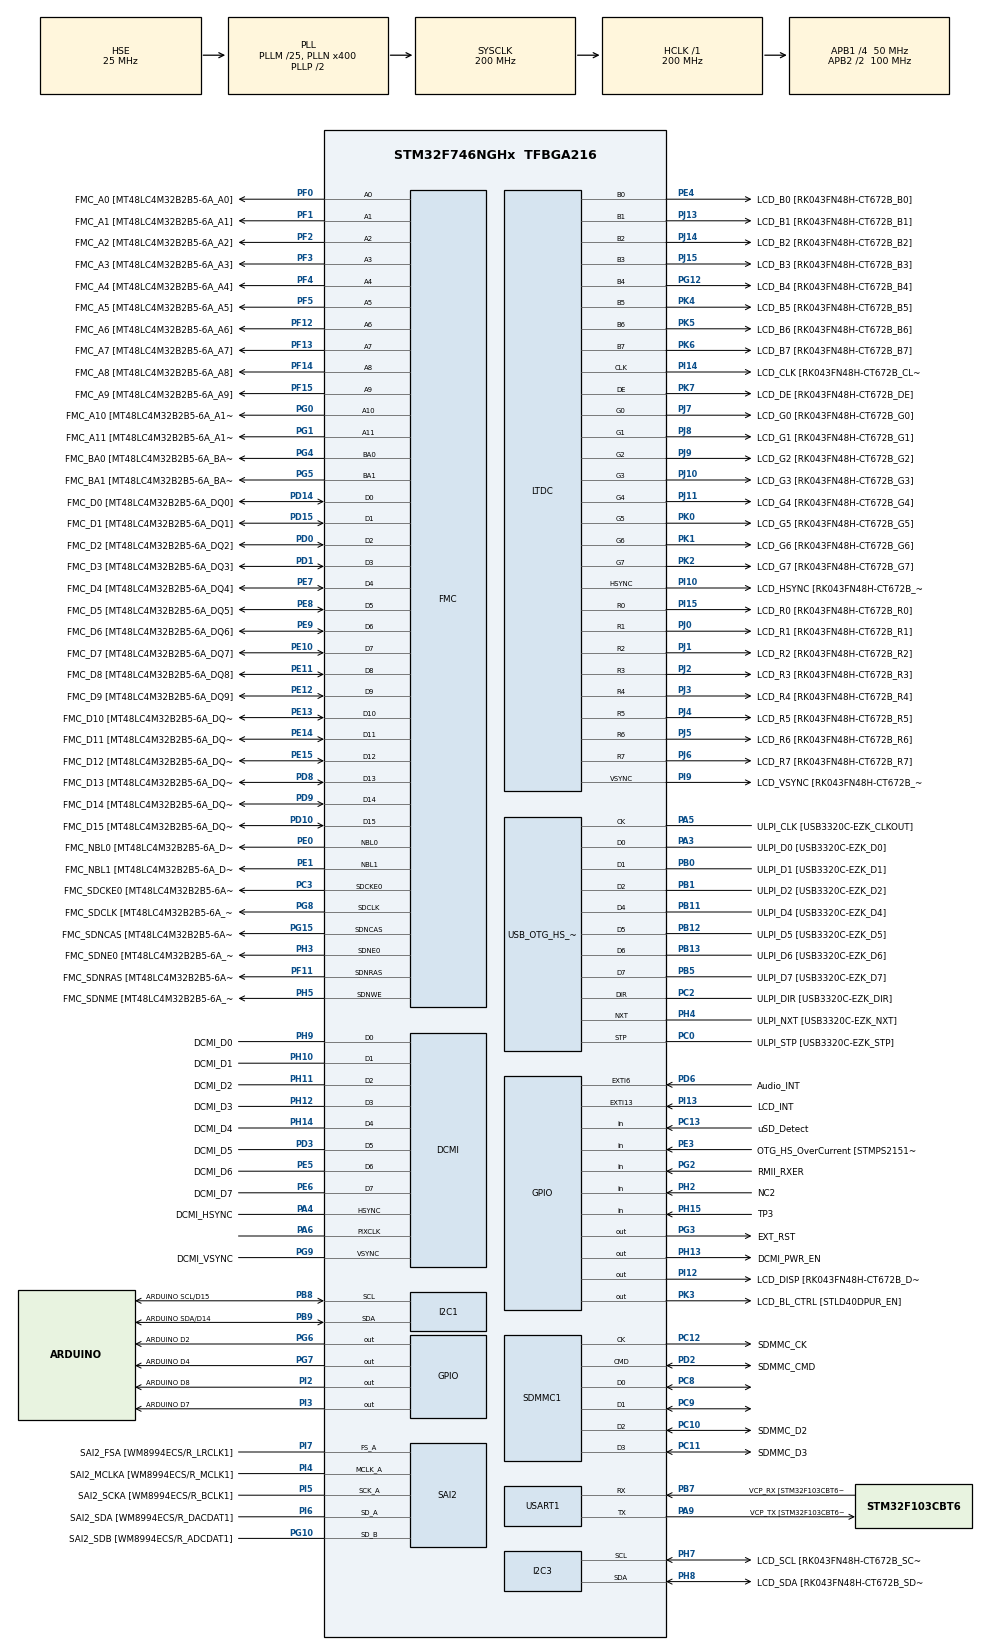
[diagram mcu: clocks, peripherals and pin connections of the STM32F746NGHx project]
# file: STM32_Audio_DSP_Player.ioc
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Dma.Request0=SDMMC1_RX
Dma.Request1=SDMMC1_TX
Dma.SDMMC1_RX.0.Direction=DMA_PERIPH_TO_MEMORY
Dma.SDMMC1_RX.0.FIFOMode=DMA_FIFOMODE_ENABLE
Dma.SDMMC1_RX.0.FIFOThreshold=DMA_FIFO_THRESHOLD_FULL
Dma.SDMMC1_RX.0.Instance=DMA2_Stream3
Dma.SDMMC1_RX.0.MemBurst=DMA_MBURST_INC4
Dma.SDMMC1_RX.0.MemDataAlignment=DMA_MDATAALIGN_WORD
Dma.SDMMC1_RX.0.MemInc=DMA_MINC_ENABLE
Dma.SDMMC1_RX.0.Mode=DMA_PFCTRL
Dma.SDMMC1_RX.0.PeriphBurst=DMA_PBURST_INC4
Dma.SDMMC1_RX.0.PeriphDataAlignment=DMA_PDATAALIGN_WORD
Dma.SDMMC1_RX.0.PeriphInc=DMA_PINC_DISABLE
Dma.SDMMC1_RX.0.Priority=DMA_PRIORITY_LOW
Dma.SDMMC1_TX.1.Direction=DMA_MEMORY_TO_PERIPH
Dma.SDMMC1_TX.1.FIFOMode=DMA_FIFOMODE_ENABLE
Dma.SDMMC1_TX.1.FIFOThreshold=DMA_FIFO_THRESHOLD_FULL
Dma.SDMMC1_TX.1.Instance=DMA2_Stream6
Dma.SDMMC1_TX.1.MemBurst=DMA_MBURST_INC4
Dma.SDMMC1_TX.1.MemDataAlignment=DMA_MDATAALIGN_WORD
Dma.SDMMC1_TX.1.MemInc=DMA_MINC_ENABLE
Dma.SDMMC1_TX.1.Mode=DMA_PFCTRL
Dma.SDMMC1_TX.1.PeriphBurst=DMA_PBURST_INC4
Dma.SDMMC1_TX.1.PeriphDataAlignment=DMA_PDATAALIGN_WORD
Dma.SDMMC1_TX.1.PeriphInc=DMA_PINC_DISABLE
Dma.SDMMC1_TX.1.Priority=DMA_PRIORITY_LOW
FATFS.BSP.number=1
FATFS0.BSP.STBoard=false
FATFS0.BSP.api=Unknown
FATFS0.BSP.instance=PC13
FATFS0.BSP.ip=GPIO
FATFS0.BSP.mode=Input
FATFS0.BSP.name=Detect_SDIO
FATFS0.BSP.solution=PC13
FMC.CASLatency1=FMC_SDRAM_CAS_LATENCY_3
FMC.ExitSelfRefreshDelay1=7
FMC.LoadToActiveDelay1=2
FMC.RCDDelay1=2
FMC.RPDelay1=2
FMC.RPDelay2=2
FMC.ReadBurst1=FMC_SDRAM_RBURST_ENABLE
FMC.ReadBurst2=FMC_SDRAM_RBURST_ENABLE
FMC.RowCycleDelay1=7
FMC.RowCycleDelay2=7
FMC.SDClockPeriod1=FMC_SDRAM_CLOCK_PERIOD_2
FMC.SDClockPeriod2=FMC_SDRAM_CLOCK_PERIOD_2
FMC.SelfRefreshTime1=4
FMC.WriteRecoveryTime1=3
FREERTOS.Tasks01=defaultTask,0,4096,StartDefaultTask,Default,NULL,Dynamic,NULL,NULL;TouchGFXTask,0,4096,TouchGFX_Task,As external,NULL,Dynamic,NULL,NULL
FREERTOS.configCHECK_FOR_STACK_OVERFLOW=2
FREERTOS.configTOTAL_HEAP_SIZE=70000
FREERTOS.configUSE_APPLICATION_TASK_TAG=1
FREERTOS.configUSE_COUNTING_SEMAPHORES=1
FREERTOS.configUSE_IDLE_HOOK=1
FREERTOS.configUSE_MALLOC_FAILED_HOOK=1
FREERTOS.configUSE_RECURSIVE_MUTEXES=1
I2C1.Timing=0x00C0EAFF
I2C3.Timing=0x00C0EAFF
LTDC.ActiveH=272
LTDC.ActiveW=480
LTDC.Alpha_L0=255
LTDC.BlendingFactor1_L0=LTDC_BLENDING_FACTOR1_PAxCA
LTDC.BlendingFactor2_L0=LTDC_BLENDING_FACTOR2_PAxCA
LTDC.FBStartAdress_L0=0xC0000000
LTDC.HBP=13
LTDC.HFP=32
LTDC.HSync=41
LTDC.ImageHeight_L0=272
LTDC.ImageWidth_L0=480
LTDC.Layers=0
LTDC.PixelFormat_L0=LTDC_PIXEL_FORMAT_RGB565
LTDC.VSync=10
LTDC.WindowX1_L0=480
LTDC.WindowY1_L0=272
Mcu.Family=STM32F7
Mcu.Name=STM32F746NGHx
Mcu.Package=TFBGA216
NVIC.DMA2D_IRQn=true\:5\:0\:false\:false\:true\:true\:true\:true\:true
NVIC.DMA2_Stream3_IRQn=true\:5\:0\:false\:false\:true\:true\:false\:true\:true
NVIC.DMA2_Stream6_IRQn=true\:5\:0\:false\:false\:true\:true\:false\:true\:true
NVIC.LTDC_IRQn=true\:5\:0\:false\:false\:true\:true\:true\:true\:true
NVIC.PriorityGroup=NVIC_PRIORITYGROUP_4
NVIC.SDMMC1_IRQn=true\:5\:0\:false\:false\:true\:true\:true\:true\:true
NVIC.TIM6_DAC_IRQn=true\:0\:0\:false\:false\:true\:false\:false\:true\:true
NVIC.TimeBase=TIM6_DAC_IRQn
NVIC.TimeBaseIP=TIM6
PA0/WKUP.GPIO_Label=ARDUINO A0
PA0/WKUP.GPIO_Mode=GPIO_MODE_ANALOG
PA0/WKUP.GPIO_PuPd=GPIO_NOPULL
PA0/WKUP.Signal=ADCx_IN0
PA1.GPIO_Label=RMII_REF_CLK [LAN8742A-CZ-TR_REFCLK0]
PA1.Signal=ETH_REF_CLK
PA13.GPIO_Label=SWDIO
PA13.Mode=Serial_Wire
PA13.Signal=SYS_JTMS-SWDIO
PA14.GPIO_Label=SWCLK
PA14.Mode=Serial_Wire
PA14.Signal=SYS_JTCK-SWCLK
PA15.GPIO_Label=ARDUINO PWM/D9
PA15.GPIO_PuPd=GPIO_NOPULL
PA15.GPIO_Speed=GPIO_SPEED_FREQ_LOW
PA15.Signal=S_TIM2_CH1_ETR
PA2.GPIO_Label=RMII_MDIO [LAN8742A-CZ-TR_MDIO]
PA2.Signal=ETH_MDIO
PA3.GPIO_Label=ULPI_D0 [USB3320C-EZK_D0]
PA3.Mode=Host_HS
PA3.Signal=USB_OTG_HS_ULPI_D0
PA4.GPIO_Label=DCMI_HSYNC
PA4.Mode=Slave_8_bits_External_Synchro
PA4.Signal=DCMI_HSYNC
PA5.GPIO_Label=ULPI_CLK [USB3320C-EZK_CLKOUT]
PA5.Mode=Host_HS
PA5.Signal=USB_OTG_HS_ULPI_CK
PA6.Mode=Slave_8_bits_External_Synchro
PA6.Signal=DCMI_PIXCLK
PA7.GPIO_Label=RMII_CRS_DV [LAN8742A-CZ-TR_CRS_DV]
PA7.Signal=ETH_CRS_DV
PA8.GPIO_Label=ARDUINO PWM/D10
PA8.GPIO_PuPd=GPIO_NOPULL
PA8.GPIO_Speed=GPIO_SPEED_FREQ_LOW
PA8.Signal=S_TIM1_CH1
PA9.GPIO_Label=VCP_TX [STM32F103CBT6_PA3]
PA9.GPIO_Mode=GPIO_MODE_AF_PP
PA9.GPIO_PuPd=GPIO_NOPULL
PA9.GPIO_Speed=GPIO_SPEED_FREQ_LOW
PA9.Mode=Asynchronous
PA9.Signal=USART1_TX
PB0.GPIO_Label=ULPI_D1 [USB3320C-EZK_D1]
PB0.Mode=Host_HS
PB0.Signal=USB_OTG_HS_ULPI_D1
PB1.GPIO_Label=ULPI_D2 [USB3320C-EZK_D2]
PB1.Mode=Host_HS
PB1.Signal=USB_OTG_HS_ULPI_D2
PB10.GPIO_Label=ULPI_D3 [USB3320C-EZK_D3]
PB10.Signal=USB_OTG_HS_ULPI_D3
PB11.GPIO_Label=ULPI_D4 [USB3320C-EZK_D4]
PB11.Mode=Host_HS
PB11.Signal=USB_OTG_HS_ULPI_D4
PB12.GPIO_Label=ULPI_D5 [USB3320C-EZK_D5]
PB12.Mode=Host_HS
PB12.Signal=USB_OTG_HS_ULPI_D5
PB13.GPIO_Label=ULPI_D6 [USB3320C-EZK_D6]
PB13.Mode=Host_HS
PB13.Signal=USB_OTG_HS_ULPI_D6
PB14.GPIO_Label=ARDUINO MISO/D12
PB14.GPIO_Mode=GPIO_MODE_AF_PP
PB14.GPIO_PuPd=GPIO_NOPULL
PB14.GPIO_Speed=GPIO_SPEED_FREQ_LOW
PB14.Signal=SPI2_MISO
PB15.GPIO_Label=ARDUINO MOSI/PWM/D11
PB15.GPIO_Mode=GPIO_MODE_AF_PP
PB15.GPIO_PuPd=GPIO_NOPULL
PB15.GPIO_Speed=GPIO_SPEED_FREQ_LOW
PB15.Signal=SPI2_MOSI
PB3.GPIO_Label=SWO
PB3.Signal=SYS_JTDO-SWO
PB5.GPIO_Label=ULPI_D7 [USB3320C-EZK_D7]
PB5.Mode=Host_HS
PB5.Signal=USB_OTG_HS_ULPI_D7
PB7.GPIO_Label=VCP_RX [STM32F103CBT6_PA2]
PB7.GPIO_Mode=GPIO_MODE_AF_PP
PB7.GPIO_PuPd=GPIO_NOPULL
PB7.GPIO_Speed=GPIO_SPEED_FREQ_LOW
PB7.Mode=Asynchronous
PB7.Signal=USART1_RX
PB8.GPIO_Label=ARDUINO SCL/D15
PB8.GPIO_Mode=GPIO_MODE_AF_OD
PB8.GPIO_Pu=GPIO_PULLUP
PB8.GPIO_PuPd=GPIO_NOPULL
PB8.GPIO_Speed=GPIO_SPEED_FREQ_LOW
PB8.Mode=I2C
PB8.Signal=I2C1_SCL
PB9.GPIO_Label=ARDUINO SDA/D14
PB9.GPIO_Mode=GPIO_MODE_AF_OD
PB9.GPIO_Pu=GPIO_PULLUP
PB9.GPIO_PuPd=GPIO_NOPULL
PB9.GPIO_Speed=GPIO_SPEED_FREQ_LOW
PB9.Mode=I2C
PB9.Signal=I2C1_SDA
PC0.GPIO_Label=ULPI_STP [USB3320C-EZK_STP]
PC0.Mode=Host_HS
PC0.Signal=USB_OTG_HS_ULPI_STP
PC1.GPIO_Label=RMII_MDC [LAN8742A-CZ-TR_MDC]
PC1.Signal=ETH_MDC
PC10.GPIO_Label=SDMMC_D2
PC10.Mode=SD_4_bits_Wide_bus
PC10.Signal=SDMMC1_D2
PC11.GPIO_Label=SDMMC_D3
PC11.Mode=SD_4_bits_Wide_bus
PC11.Signal=SDMMC1_D3
PC12.GPIO_Label=SDMMC_CK
PC12.Mode=SD_4_bits_Wide_bus
PC12.Signal=SDMMC1_CK
PC13.GPIO_Label=uSD_Detect
PC13.GPIO_PuPd=GPIO_PULLUP
PC13.Signal=GPIO_Input
PC14/OSC32_IN.GPIO_Label=RCC_OSC32_IN
PC14/OSC32_IN.Mode=LSE-External-Oscillator
PC14/OSC32_IN.Signal=RCC_OSC32_IN
PC15/OSC32_OUT.GPIO_Label=RCC_OSC32_OUT
PC15/OSC32_OUT.Mode=LSE-External-Oscillator
PC15/OSC32_OUT.Signal=RCC_OSC32_OUT
PC2.GPIO_Label=ULPI_DIR [USB3320C-EZK_DIR]
PC2.Mode=Host_HS
PC2.Signal=USB_OTG_HS_ULPI_DIR
PC3.GPIO_Label=FMC_SDCKE0 [MT48LC4M32B2B5-6A_CKE]
PC3.Mode=SdramChipSelect1_1
PC3.Signal=FMC_SDCKE0
PC4.GPIO_Label=RMII_RXD0 [LAN8742A-CZ-TR_RXD0]
PC4.Signal=ETH_RXD0
PC5.GPIO_Label=RMII_RXD1 [LAN8742A-CZ-TR_RXD1]
PC5.Signal=ETH_RXD1
PC8.Mode=SD_4_bits_Wide_bus
PC8.Signal=SDMMC1_D0
PC9.Mode=SD_4_bits_Wide_bus
PC9.Signal=SDMMC1_D1
PD0.GPIO_Label=FMC_D2 [MT48LC4M32B2B5-6A_DQ2]
PD0.Signal=FMC_D2_DA2
PD1.GPIO_Label=FMC_D3 [MT48LC4M32B2B5-6A_DQ3]
PD1.Signal=FMC_D3_DA3
PD10.GPIO_Label=FMC_D15 [MT48LC4M32B2B5-6A_DQ15]
PD10.Signal=FMC_D15_DA15
PD14.GPIO_Label=FMC_D0 [MT48LC4M32B2B5-6A_DQ0]
PD14.Signal=FMC_D0_DA0
PD15.GPIO_Label=FMC_D1 [MT48LC4M32B2B5-6A_DQ1]
PD15.Signal=FMC_D1_DA1
PD2.GPIO_Label=SDMMC_CMD
PD2.Mode=SD_4_bits_Wide_bus
PD2.Signal=SDMMC1_CMD
PD3.GPIO_Label=DCMI_D5
PD3.Mode=Slave_8_bits_External_Synchro
PD3.Signal=DCMI_D5
PD6.GPIO_Label=Audio_INT
PD6.GPIO_ModeDefaultEXTI=GPIO_MODE_EVT_RISING
PD6.Signal=GPXTI6
PD7.GPIO_Label=SPDIF_RX0 [74LVC1G04SE_4]
PD7.Signal=SPDIFRX_IN0
PD8.GPIO_Label=FMC_D13 [MT48LC4M32B2B5-6A_DQ13]
PD8.Signal=FMC_D13_DA13
PD9.GPIO_Label=FMC_D14 [MT48LC4M32B2B5-6A_DQ14]
PD9.Signal=FMC_D14_DA14
PE0.GPIO_Label=FMC_NBL0 [MT48LC4M32B2B5-6A_DQM0]
PE0.Signal=FMC_NBL0
PE1.GPIO_Label=FMC_NBL1 [MT48LC4M32B2B5-6A_DQM1]
PE1.Signal=FMC_NBL1
PE10.GPIO_Label=FMC_D7 [MT48LC4M32B2B5-6A_DQ7]
PE10.Signal=FMC_D7_DA7
PE11.GPIO_Label=FMC_D8 [MT48LC4M32B2B5-6A_DQ8]
PE11.Signal=FMC_D8_DA8
PE12.GPIO_Label=FMC_D9 [MT48LC4M32B2B5-6A_DQ9]
PE12.Signal=FMC_D9_DA9
PE13.GPIO_Label=FMC_D10 [MT48LC4M32B2B5-6A_DQ10]
PE13.Signal=FMC_D10_DA10
PE14.GPIO_Label=FMC_D11 [MT48LC4M32B2B5-6A_DQ11]
PE14.Signal=FMC_D11_DA11
PE15.GPIO_Label=FMC_D12 [MT48LC4M32B2B5-6A_DQ12]
PE15.Signal=FMC_D12_DA12
PE3.GPIO_Label=OTG_HS_OverCurrent [STMPS2151STR_FAULT]
PE3.Signal=GPIO_Input
PE4.GPIO_Label=LCD_B0 [RK043FN48H-CT672B_B0]
PE4.Mode=RGB888
PE4.Signal=LTDC_B0
PE5.GPIO_Label=DCMI_D6
PE5.Mode=Slave_8_bits_External_Synchro
PE5.Signal=DCMI_D6
PE6.GPIO_Label=DCMI_D7
PE6.Mode=Slave_8_bits_External_Synchro
PE6.Signal=DCMI_D7
PE7.GPIO_Label=FMC_D4 [MT48LC4M32B2B5-6A_DQ4]
PE7.Signal=FMC_D4_DA4
PE8.GPIO_Label=FMC_D5 [MT48LC4M32B2B5-6A_DQ5]
PE8.Signal=FMC_D5_DA5
PE9.GPIO_Label=FMC_D6 [MT48LC4M32B2B5-6A_DQ6]
PE9.Signal=FMC_D6_DA6
PF0.GPIO_Label=FMC_A0 [MT48LC4M32B2B5-6A_A0]
PF0.Signal=FMC_A0
PF1.GPIO_Label=FMC_A1 [MT48LC4M32B2B5-6A_A1]
PF1.Signal=FMC_A1
PF10.GPIO_Label=ARDUINO A1
PF10.GPIO_Mode=GPIO_MODE_ANALOG
PF10.GPIO_PuPd=GPIO_NOPULL
PF10.Signal=ADC3_IN8
PF11.GPIO_Label=FMC_SDNRAS [MT48LC4M32B2B5-6A_RAS]
PF11.Signal=FMC_SDNRAS
PF12.GPIO_Label=FMC_A6 [MT48LC4M32B2B5-6A_A6]
PF12.Signal=FMC_A6
PF13.GPIO_Label=FMC_A7 [MT48LC4M32B2B5-6A_A7]
PF13.Signal=FMC_A7
PF14.GPIO_Label=FMC_A8 [MT48LC4M32B2B5-6A_A8]
PF14.Signal=FMC_A8
PF15.GPIO_Label=FMC_A9 [MT48LC4M32B2B5-6A_A9]
PF15.Signal=FMC_A9
PF2.GPIO_Label=FMC_A2 [MT48LC4M32B2B5-6A_A2]
PF2.Signal=FMC_A2
PF3.GPIO_Label=FMC_A3 [MT48LC4M32B2B5-6A_A3]
PF3.Signal=FMC_A3
PF4.GPIO_Label=FMC_A4 [MT48LC4M32B2B5-6A_A4]
PF4.Signal=FMC_A4
PF5.GPIO_Label=FMC_A5 [MT48LC4M32B2B5-6A_A5]
PF5.Signal=FMC_A5
PF6.GPIO_Label=ARDUINO A5
PF6.GPIO_Mode=GPIO_MODE_ANALOG
PF6.GPIO_PuPd=GPIO_NOPULL
PF6.Signal=ADC3_IN4
PF7.GPIO_Label=ARDUINO A4
PF7.GPIO_Mode=GPIO_MODE_ANALOG
PF7.GPIO_PuPd=GPIO_NOPULL
PF7.Signal=ADC3_IN5
PF8.GPIO_Label=ARDUINO A3
PF8.GPIO_Mode=GPIO_MODE_ANALOG
PF8.GPIO_PuPd=GPIO_NOPULL
PF8.Signal=ADC3_IN6
PF9.GPIO_Label=ARDUINO A2
PF9.GPIO_Mode=GPIO_MODE_ANALOG
PF9.GPIO_PuPd=GPIO_NOPULL
PF9.Signal=ADC3_IN7
PG0.GPIO_Label=FMC_A10 [MT48LC4M32B2B5-6A_A10]
PG0.Signal=FMC_A10
PG1.GPIO_Label=FMC_A11 [MT48LC4M32B2B5-6A_A11]
PG1.Signal=FMC_A11
PG10.GPIO_Label=SAI2_SDB [WM8994ECS/R_ADCDAT1]
PG10.Mode=SAI_B_SyncSlave
PG10.Signal=SAI2_SD_B
PG11.GPIO_Label=RMII_TX_EN [LAN8742A-CZ-TR_TXEN]
PG11.Signal=ETH_TX_EN
PG12.GPIO_Label=LCD_B4 [RK043FN48H-CT672B_B4]
PG12.Mode=RGB888
PG12.Signal=LTDC_B4
PG13.GPIO_Label=RMII_TXD0 [LAN8742A-CZ-TR_TXD0]
PG13.Signal=ETH_TXD0
PG14.GPIO_Label=RMII_TXD1 [LAN8742A-CZ-TR_TXD1]
PG14.Signal=ETH_TXD1
PG15.GPIO_Label=FMC_SDNCAS [MT48LC4M32B2B5-6A_CAS]
PG15.Signal=FMC_SDNCAS
PG2.GPIO_Label=RMII_RXER
PG2.Signal=GPIO_Input
PG3.GPIO_Label=EXT_RST
PG3.Signal=GPIO_Output
PG4.GPIO_Label=FMC_BA0 [MT48LC4M32B2B5-6A_BA0]
PG4.Signal=FMC_A14_BA0
PG5.GPIO_Label=FMC_BA1 [MT48LC4M32B2B5-6A_BA1]
PG5.Signal=FMC_A15_BA1
PG6.GPIO_Label=ARDUINO D2
PG6.Signal=GPIO_Output
PG7.GPIO_Label=ARDUINO D4
PG7.Signal=GPIO_Output
PG8.GPIO_Label=FMC_SDCLK [MT48LC4M32B2B5-6A_CLK]
PG8.Signal=FMC_SDCLK
PG9.GPIO_Label=DCMI_VSYNC
PG9.Mode=Slave_8_bits_External_Synchro
PG9.Signal=DCMI_VSYNC
PH0/OSC_IN.GPIO_Label=OSC_25M [NZ2520SB-25.00M_OUT]
PH0/OSC_IN.Mode=HSE-External-Oscillator
PH0/OSC_IN.Signal=RCC_OSC_IN
PH1/OSC_OUT.Mode=HSE-External-Oscillator
PH1/OSC_OUT.Signal=RCC_OSC_OUT
PH10.GPIO_Label=DCMI_D1
PH10.Mode=Slave_8_bits_External_Synchro
PH10.Signal=DCMI_D1
PH11.GPIO_Label=DCMI_D2
PH11.Mode=Slave_8_bits_External_Synchro
PH11.Signal=DCMI_D2
PH12.GPIO_Label=DCMI_D3
PH12.Mode=Slave_8_bits_External_Synchro
PH12.Signal=DCMI_D3
PH13.GPIO_Label=DCMI_PWR_EN
PH13.Signal=GPIO_Output
PH14.GPIO_Label=DCMI_D4
PH14.Mode=Slave_8_bits_External_Synchro
PH14.Signal=DCMI_D4
PH15.GPIO_Label=TP3
PH15.Signal=GPIO_Input
PH2.GPIO_Label=NC2
PH2.Signal=GPIO_Input
PH3.GPIO_Label=FMC_SDNE0 [MT48LC4M32B2B5-6A_CS]
PH3.Mode=SdramChipSelect1_1
PH3.Signal=FMC_SDNE0
PH4.GPIO_Label=ULPI_NXT [USB3320C-EZK_NXT]
PH4.Mode=Host_HS
PH4.Signal=USB_OTG_HS_ULPI_NXT
PH5.GPIO_Label=FMC_SDNME [MT48LC4M32B2B5-6A_WE]
PH5.Signal=FMC_SDNWE
PH7.GPIO_Label=LCD_SCL [RK043FN48H-CT672B_SCL]
PH7.GPIO_Pu=GPIO_PULLUP
PH7.Mode=I2C
PH7.Signal=I2C3_SCL
PH8.GPIO_Label=LCD_SDA [RK043FN48H-CT672B_SDA]
PH8.GPIO_Pu=GPIO_PULLUP
PH8.Mode=I2C
PH8.Signal=I2C3_SDA
PH9.GPIO_Label=DCMI_D0
PH9.Mode=Slave_8_bits_External_Synchro
PH9.Signal=DCMI_D0
PI1.GPIO_Label=ARDUINO SCK/D13
PI1.GPIO_Mode=GPIO_MODE_AF_PP
PI1.GPIO_PuPd=GPIO_NOPULL
PI1.GPIO_Speed=GPIO_SPEED_FREQ_LOW
PI1.Signal=SPI2_SCK
PI10.GPIO_Label=LCD_HSYNC [RK043FN48H-CT672B_HSYNC]
PI10.Mode=RGB888
PI10.Signal=LTDC_HSYNC
PI12.GPIO_Label=LCD_DISP [RK043FN48H-CT672B_DISP] 
PI12.PinState=GPIO_PIN_SET
PI12.Signal=GPIO_Output
PI13.GPIO_Label=LCD_INT
PI13.GPIO_ModeDefaultEXTI=GPIO_MODE_EVT_RISING
PI13.Signal=GPXTI13
PI14.GPIO_Label=LCD_CLK [RK043FN48H-CT672B_CLK]
PI14.Mode=RGB888
PI14.Signal=LTDC_CLK
PI15.GPIO_Label=LCD_R0 [RK043FN48H-CT672B_R0]
PI15.Mode=RGB888
PI15.Signal=LTDC_R0
PI2.GPIO_Label=ARDUINO D8
PI2.Signal=GPIO_Output
PI3.GPIO_Label=ARDUINO D7
PI3.Signal=GPIO_Output
PI4.GPIO_Label=SAI2_MCLKA [WM8994ECS/R_MCLK1]
PI4.Mode=SAI_A_MasterWithClock
PI4.Signal=SAI2_MCLK_A
PI5.GPIO_Label=SAI2_SCKA [WM8994ECS/R_BCLK1]
PI5.Mode=SAI_A_MasterWithClock
PI5.Signal=SAI2_SCK_A
PI6.GPIO_Label=SAI2_SDA [WM8994ECS/R_DACDAT1]
PI6.Mode=SAI_A_MasterWithClock
PI6.Signal=SAI2_SD_A
PI7.GPIO_Label=SAI2_FSA [WM8994ECS/R_LRCLK1]
PI7.Mode=SAI_A_MasterWithClock
PI7.Signal=SAI2_FS_A
PI8.GPIO_Label=NC1 [TP2]
PI8.Signal=RTC_TS
PI9.GPIO_Label=LCD_VSYNC [RK043FN48H-CT672B_VSYNC]
PI9.Mode=RGB888
PI9.Signal=LTDC_VSYNC
PJ0.GPIO_Label=LCD_R1 [RK043FN48H-CT672B_R1]
PJ0.Mode=RGB888
PJ0.Signal=LTDC_R1
PJ1.GPIO_Label=LCD_R2 [RK043FN48H-CT672B_R2]
PJ1.Mode=RGB888
PJ1.Signal=LTDC_R2
PJ10.GPIO_Label=LCD_G3 [RK043FN48H-CT672B_G3]
PJ10.Mode=RGB888
PJ10.Signal=LTDC_G3
PJ11.GPIO_Label=LCD_G4 [RK043FN48H-CT672B_G4]
PJ11.Mode=RGB888
PJ11.Signal=LTDC_G4
PJ13.GPIO_Label=LCD_B1 [RK043FN48H-CT672B_B1]
PJ13.Mode=RGB888
PJ13.Signal=LTDC_B1
PJ14.GPIO_Label=LCD_B2 [RK043FN48H-CT672B_B2]
PJ14.Mode=RGB888
PJ14.Signal=LTDC_B2
PJ15.GPIO_Label=LCD_B3 [RK043FN48H-CT672B_B3]
PJ15.Mode=RGB888
PJ15.Signal=LTDC_B3
PJ2.GPIO_Label=LCD_R3 [RK043FN48H-CT672B_R3]
PJ2.Mode=RGB888
PJ2.Signal=LTDC_R3
PJ3.GPIO_Label=LCD_R4 [RK043FN48H-CT672B_R4]
PJ3.Mode=RGB888
PJ3.Signal=LTDC_R4
PJ4.GPIO_Label=LCD_R5 [RK043FN48H-CT672B_R5]
PJ4.Mode=RGB888
PJ4.Signal=LTDC_R5
PJ5.GPIO_Label=LCD_R6 [RK043FN48H-CT672B_R6]
PJ5.Mode=RGB888
PJ5.Signal=LTDC_R6
PJ6.GPIO_Label=LCD_R7 [RK043FN48H-CT672B_R7]
PJ6.Mode=RGB888
PJ6.Signal=LTDC_R7
PJ7.GPIO_Label=LCD_G0 [RK043FN48H-CT672B_G0]
PJ7.Mode=RGB888
PJ7.Signal=LTDC_G0
PJ8.GPIO_Label=LCD_G1 [RK043FN48H-CT672B_G1]
PJ8.Mode=RGB888
PJ8.Signal=LTDC_G1
PJ9.GPIO_Label=LCD_G2 [RK043FN48H-CT672B_G2]
PJ9.Mode=RGB888
PJ9.Signal=LTDC_G2
PK0.GPIO_Label=LCD_G5 [RK043FN48H-CT672B_G5]
PK0.Mode=RGB888
PK0.Signal=LTDC_G5
PK1.GPIO_Label=LCD_G6 [RK043FN48H-CT672B_G6]
PK1.Mode=RGB888
PK1.Signal=LTDC_G6
PK2.GPIO_Label=LCD_G7 [RK043FN48H-CT672B_G7]
PK2.Mode=RGB888
PK2.Signal=LTDC_G7
PK3.GPIO_Label=LCD_BL_CTRL [STLD40DPUR_EN]
PK3.GPIO_Speed=GPIO_SPEED_FREQ_LOW
PK3.PinState=GPIO_PIN_SET
PK3.Signal=GPIO_Output
PK4.GPIO_Label=LCD_B5 [RK043FN48H-CT672B_B5]
PK4.Mode=RGB888
PK4.Signal=LTDC_B5
PK5.GPIO_Label=LCD_B6 [RK043FN48H-CT672B_B6]
PK5.Mode=RGB888
PK5.Signal=LTDC_B6
PK6.GPIO_Label=LCD_B7 [RK043FN48H-CT672B_B7]
PK6.Mode=RGB888
PK6.Signal=LTDC_B7
PK7.GPIO_Label=LCD_DE [RK043FN48H-CT672B_DE]
PK7.Mode=RGB888
PK7.Signal=LTDC_DE
ProjectManager.HeapSize=0x200
ProjectManager.StackSize=0x400
ProjectManager.TargetToolchain=STM32CubeIDE
RCC.AHBFreq_Value=200000000
RCC.APB1CLKDivider=RCC_HCLK_DIV4
RCC.APB1Freq_Value=50000000
RCC.APB1TimFreq_Value=100000000
RCC.APB2CLKDivider=RCC_HCLK_DIV2
RCC.APB2Freq_Value=100000000
RCC.APB2TimFreq_Value=200000000
RCC.CortexFreq_Value=200000000
RCC.HCLKFreq_Value=200000000
RCC.HSE_VALUE=25000000
RCC.HSI_VALUE=16000000
RCC.PLL48CLockSelection=RCC_CLK48SOURCE_PLLSAIP
RCC.PLLI2SN=100
RCC.PLLM=25
RCC.PLLN=400
RCC.PLLQ=9
RCC.PLLSAIN=384
RCC.PLLSAIP=RCC_PLLSAIP_DIV8
RCC.PLLSAIR=5
RCC.PLLSAIRDiv=RCC_PLLSAIDIVR_8
RCC.SDMMCClockSelection=RCC_SDMMC1CLKSOURCE_CLK48
RCC.SYSCLKFreq_VALUE=200000000
RCC.SYSCLKSource=RCC_SYSCLKSOURCE_PLLCLK
RCC.USBFreq_Value=48000000
RCC.VCOOutputFreq_Value=400000000
SAI2.ErrorAudioFreq-SAI_A_MasterWithClock=-2.34 %
SAI2.Instance-SAI_A_MasterWithClock=SAI$Index_Block_A
SAI2.Instance-SAI_B_SyncSlave=SAI$Index_Block_B
SAI2.MClockEnable-SAI_A_MasterWithClock=SAI_MASTERCLOCK_ENABLE
SAI2.RealAudioFreq-SAI_A_MasterWithClock=187.5 KHz
SAI2.Synchro-SAI_B_SyncSlave=SAI_SYNCHRONOUS
SAI2.VirtualMode-SAI_A_MasterWithClock=VM_MASTER
SAI2.VirtualMode-SAI_B_SyncSlave=VM_SLAVE
SDMMC1.WideMode=SDMMC_BUS_WIDE_4B
SH.ADCx_IN0.0=ADC3_IN0
SH.FMC_A0.0=FMC_A0,12b-sda1
SH.FMC_A1.0=FMC_A1,12b-sda1
SH.FMC_A10.0=FMC_A10,12b-sda1
SH.FMC_A11.0=FMC_A11,12b-sda1
SH.FMC_A14_BA0.0=FMC_BA0,FourSdramBanks1
SH.FMC_A15_BA1.0=FMC_BA1,FourSdramBanks1
SH.FMC_A2.0=FMC_A2,12b-sda1
SH.FMC_A3.0=FMC_A3,12b-sda1
SH.FMC_A4.0=FMC_A4,12b-sda1
SH.FMC_A5.0=FMC_A5,12b-sda1
SH.FMC_A6.0=FMC_A6,12b-sda1
SH.FMC_A7.0=FMC_A7,12b-sda1
SH.FMC_A8.0=FMC_A8,12b-sda1
SH.FMC_A9.0=FMC_A9,12b-sda1
SH.FMC_D0_DA0.0=FMC_D0,sd-16b-d1
SH.FMC_D10_DA10.0=FMC_D10,sd-16b-d1
SH.FMC_D11_DA11.0=FMC_D11,sd-16b-d1
SH.FMC_D12_DA12.0=FMC_D12,sd-16b-d1
SH.FMC_D13_DA13.0=FMC_D13,sd-16b-d1
SH.FMC_D14_DA14.0=FMC_D14,sd-16b-d1
SH.FMC_D15_DA15.0=FMC_D15,sd-16b-d1
SH.FMC_D1_DA1.0=FMC_D1,sd-16b-d1
SH.FMC_D2_DA2.0=FMC_D2,sd-16b-d1
SH.FMC_D3_DA3.0=FMC_D3,sd-16b-d1
SH.FMC_D4_DA4.0=FMC_D4,sd-16b-d1
SH.FMC_D5_DA5.0=FMC_D5,sd-16b-d1
SH.FMC_D6_DA6.0=FMC_D6,sd-16b-d1
SH.FMC_D7_DA7.0=FMC_D7,sd-16b-d1
SH.FMC_D8_DA8.0=FMC_D8,sd-16b-d1
SH.FMC_D9_DA9.0=FMC_D9,sd-16b-d1
SH.FMC_NBL0.0=FMC_NBL0,Sd2ByteEnable1
SH.FMC_NBL1.0=FMC_NBL1,Sd2ByteEnable1
SH.FMC_SDCLK.0=FMC_SDCLK,12b-sda1
SH.FMC_SDNCAS.0=FMC_SDNCAS,12b-sda1
SH.FMC_SDNRAS.0=FMC_SDNRAS,12b-sda1
SH.FMC_SDNWE.0=FMC_SDNWE,12b-sda1
STMicroelectronics.X-CUBE-TOUCHGFX.4.26.1.ApplicationCcGraphicsJjApplication=TouchGFXOoGenerator
STMicroelectronics.X-CUBE-TOUCHGFX.4.26.1.tgfx_address1=0xC0000000
STMicroelectronics.X-CUBE-TOUCHGFX.4.26.1.tgfx_display_interface=disp_ltdc
STMicroelectronics.X-CUBE-TOUCHGFX.4.26.1.tgfx_hardware_accelerator=dma_2d
STMicroelectronics.X-CUBE-TOUCHGFX.4.26.1.tgfx_location=By Address
STMicroelectronics.X-CUBE-TOUCHGFX.4.26.1.tgfx_vsync=vsync_ltdc
STMicroelectronics.X-CUBE-TOUCHGFX.4.26.1_IsPackSelfContextualization=true
USART1.VirtualMode-Asynchronous=VM_ASYNC
VP_CRC_VS_CRC.Mode=CRC_Activate
VP_DMA2D_VS_DMA2D.Mode=DMA2D_Activate
VP_FATFS_VS_SDIO.Mode=SDIO
VP_FREERTOS_VS_CMSIS_V1.Mode=CMSIS_V1
VP_STMicroelectronics.X-CUBE-TOUCHGFX_VS_GraphicsJjApplication_4.26.1.Mode=GraphicsJjApplication
VP_SYS_VS_tim6.Mode=TIM6
board=STM32F746G-DISCO

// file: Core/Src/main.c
/* USER CODE BEGIN Header */
/**
  ******************************************************************************
  * @file           : main.c
  * @brief          : Main program body
  ******************************************************************************
  * @attention
  *
  * Copyright (c) 2026 STMicroelectronics.
  * All rights reserved.
  *
  * This software is licensed under terms that can be found in the LICENSE file
  * in the root directory of this software component.
  * If no LICENSE file comes with this software, it is provided AS-IS.
  *
  ******************************************************************************
  */
/* USER CODE END Header */
#include "main.h"
#include "cmsis_os.h"
#include "crc.h"
#include "dma.h"
#include "dma2d.h"
#include "fatfs.h"
#include "i2c.h"
#include "ltdc.h"
#include "sai.h"
#include "sdmmc.h"
#include "usart.h"
#include "gpio.h"
#include "fmc.h"
#include "app_touchgfx.h"

/* USER CODE BEGIN Includes */
#include <stdio.h>
#include "audio_spectrum.h"
/* USER CODE END Includes */

/* USER CODE BEGIN PV */
extern volatile uint8_t AudioVolume;

/* USER CODE END PV */

void SystemClock_Config(void);
void PeriphCommonClock_Config(void);
void MX_FREERTOS_Init(void);

int main(void)
{

  /* MCU Configuration--------------------------------------------------------*/

  /* Reset of all peripherals, Initializes the Flash interface and the Systick. */
  HAL_Init();

  /* Configure the system clock */
  SystemClock_Config();

  /* Configure the peripherals common clocks */
  PeriphCommonClock_Config();

  /* Initialize all configured peripherals */
  MX_GPIO_Init();
  MX_DMA_Init();
  MX_CRC_Init();
  MX_DMA2D_Init();
  MX_FMC_Init();
  MX_I2C1_Init();
  MX_I2C3_Init();
  MX_LTDC_Init();
  MX_SAI2_Init();
  MX_SDMMC1_SD_Init();
  MX_USART1_UART_Init();
  MX_FATFS_Init();
  MX_TouchGFX_Init();
  /* Call PreOsInit function */
  MX_TouchGFX_PreOSInit();
  /* USER CODE BEGIN 2 */
  AudioSpectrum_Init();
  /* USER CODE END 2 */

  /* Call init function for freertos objects (in cmsis_os2.c) */
  MX_FREERTOS_Init();

  /* Start scheduler */
  osKernelStart();

  /* We should never get here as control is now taken by the scheduler */

  /* Infinite loop */
  while (1)
  {

  }
}

void SystemClock_Config(void)
{
  RCC_OscInitTypeDef RCC_OscInitStruct = {0};
  RCC_ClkInitTypeDef RCC_ClkInitStruct = {0};

  /** Configure LSE Drive Capability
  */
  HAL_PWR_EnableBkUpAccess();

  /** Configure the main internal regulator output voltage
  */
  __HAL_RCC_PWR_CLK_ENABLE();
  __HAL_PWR_VOLTAGESCALING_CONFIG(PWR_REGULATOR_VOLTAGE_SCALE1);

  /** Initializes the RCC Oscillators according to the specified parameters
  * in the RCC_OscInitTypeDef structure.
  */
  RCC_OscInitStruct.OscillatorType = RCC_OSCILLATORTYPE_LSI|RCC_OSCILLATORTYPE_HSE;
  RCC_OscInitStruct.HSEState = RCC_HSE_ON;
  RCC_OscInitStruct.LSIState = RCC_LSI_ON;
  RCC_OscInitStruct.PLL.PLLState = RCC_PLL_ON;
  RCC_OscInitStruct.PLL.PLLSource = RCC_PLLSOURCE_HSE;
  RCC_OscInitStruct.PLL.PLLM = 25;
  RCC_OscInitStruct.PLL.PLLN = 400;
  RCC_OscInitStruct.PLL.PLLP = RCC_PLLP_DIV2;
  RCC_OscInitStruct.PLL.PLLQ = 9;
  if (HAL_RCC_OscConfig(&RCC_OscInitStruct) != HAL_OK)
  {
    Error_Handler();
  }

  /** Activate the Over-Drive mode
  */
  if (HAL_PWREx_EnableOverDrive() != HAL_OK)
  {
    Error_Handler();
  }

  /** Initializes the CPU, AHB and APB buses clocks
  */
  RCC_ClkInitStruct.ClockType = RCC_CLOCKTYPE_HCLK|RCC_CLOCKTYPE_SYSCLK
                              |RCC_CLOCKTYPE_PCLK1|RCC_CLOCKTYPE_PCLK2;
  RCC_ClkInitStruct.SYSCLKSource = RCC_SYSCLKSOURCE_PLLCLK;
  RCC_ClkInitStruct.AHBCLKDivider = RCC_SYSCLK_DIV1;
  RCC_ClkInitStruct.APB1CLKDivider = RCC_HCLK_DIV4;
  RCC_ClkInitStruct.APB2CLKDivider = RCC_HCLK_DIV2;

  if (HAL_RCC_ClockConfig(&RCC_ClkInitStruct, FLASH_LATENCY_6) != HAL_OK)
  {
    Error_Handler();
  }
}

void PeriphCommonClock_Config(void)
{
  RCC_PeriphCLKInitTypeDef PeriphClkInitStruct = {0};

  /** Initializes the peripherals clock
  */
  PeriphClkInitStruct.PeriphClockSelection = RCC_PERIPHCLK_LTDC|RCC_PERIPHCLK_SAI2
                              |RCC_PERIPHCLK_SDMMC1|RCC_PERIPHCLK_CLK48;
  PeriphClkInitStruct.PLLSAI.PLLSAIN = 384;
  PeriphClkInitStruct.PLLSAI.PLLSAIR = 5;
  PeriphClkInitStruct.PLLSAI.PLLSAIQ = 2;
  PeriphClkInitStruct.PLLSAI.PLLSAIP = RCC_PLLSAIP_DIV8;
  PeriphClkInitStruct.PLLSAIDivQ = 1;
  PeriphClkInitStruct.PLLSAIDivR = RCC_PLLSAIDIVR_8;
  PeriphClkInitStruct.Sai2ClockSelection = RCC_SAI2CLKSOURCE_PLLSAI;
  PeriphClkInitStruct.Clk48ClockSelection = RCC_CLK48SOURCE_PLLSAIP;
  PeriphClkInitStruct.Sdmmc1ClockSelection = RCC_SDMMC1CLKSOURCE_CLK48;
  if (HAL_RCCEx_PeriphCLKConfig(&PeriphClkInitStruct) != HAL_OK)
  {
    Error_Handler();
  }
}

/* USER CODE BEGIN 4 */
int __io_putchar(int ch)
{
  HAL_UART_Transmit(&huart1, (uint8_t *)&ch, 1, HAL_MAX_DELAY);
  return ch;
}

int _write(int file, char *ptr, int len)
{
  HAL_UART_Transmit(&huart1, (uint8_t *)ptr, len, HAL_MAX_DELAY);
  return len;
}

/* USER CODE END 4 */

void HAL_TIM_PeriodElapsedCallback(TIM_HandleTypeDef *htim)
{
  if (htim->Instance == TIM6) {
    HAL_IncTick();
  }
}

void Error_Handler(void)
{
  __disable_irq();
  while (1)
  {
  }
}

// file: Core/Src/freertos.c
/* USER CODE BEGIN Header */
/**
  ******************************************************************************
  * File Name          : freertos.c
  * Description        : Code for freertos applications
  ******************************************************************************
  * @attention
  *
  * Copyright (c) 2026 STMicroelectronics.
  * All rights reserved.
  *
  * This software is licensed under terms that can be found in the LICENSE file
  * in the root directory of this software component.
  * If no LICENSE file comes with this software, it is provided AS-IS.
  *
  ******************************************************************************
  */
/* USER CODE END Header */

#include "FreeRTOS.h"
#include "task.h"
#include "main.h"
#include "cmsis_os.h"

/* USER CODE BEGIN Includes */
#include "stm32746g_discovery_audio.h"
#include "fatfs.h"
#include <stdio.h>
#include "sdmmc.h"
#include "audio_pipeline.h"
#include "audio_benchmark.h"
#include "audio_spectrum.h"
#include "audio_player.h"
#include <string.h>

extern SD_HandleTypeDef hsd1;

/* USER CODE END Includes */

/* USER CODE BEGIN Variables */

typedef enum
{
    PLAYER_STOPPED = 0,
    PLAYER_PLAYING,
    PLAYER_PAUSED
} PlayerState_t;

volatile PlayerState_t PlayerState = PLAYER_STOPPED;

volatile uint8_t AudioPlayPauseRequested = 0;

#define PLAYLIST_MAX_TRACKS 32U
#define PLAYLIST_FILENAME_SIZE 128U

static char playlist[PLAYLIST_MAX_TRACKS][PLAYLIST_FILENAME_SIZE];
static uint16_t trackCount;

volatile int currentTrack = 0;

volatile int8_t AudioTrackChangePending = 0;
volatile int8_t AudioVolumeChangePending = 0;

volatile uint8_t AudioVolume = 70;

/* The LCD only needs about 23 spectrum updates per second. */
static uint8_t spectrumDecimationCounter;

/* USER CODE END Variables */
osThreadId defaultTaskHandle;
osThreadId TouchGFXTaskHandle;

/* USER CODE BEGIN FunctionPrototypes */
static void AudioPlayer_ClearTransferFlags(void);
static uint8_t AudioPlayer_ScanPlaylist(void);
static uint8_t AudioPlayer_IsWavFile(const char *filename);
static void AudioPlayer_SortPlaylist(void);
static uint8_t AudioPlayer_StartSelectedTrack(const char *reason);
static uint8_t AudioPlayer_ChangeTrack(int8_t delta, const char *reason);
static void AudioPlayer_ServiceBuffer(uint8_t *buffer);
/* USER CODE END FunctionPrototypes */

void StartDefaultTask(void const * argument);
extern void TouchGFX_Task(void const * argument);

void MX_FREERTOS_Init(void); /* (MISRA C 2004 rule 8.1) */

/* GetIdleTaskMemory prototype (linked to static allocation support) */
void vApplicationGetIdleTaskMemory( StaticTask_t **ppxIdleTaskTCBBuffer, StackType_t **ppxIdleTaskStackBuffer, uint32_t *pulIdleTaskStackSize );

/* Hook prototypes */
void vApplicationIdleHook(void);
void vApplicationStackOverflowHook(xTaskHandle xTask, signed char *pcTaskName);
void vApplicationMallocFailedHook(void);

/* USER CODE BEGIN 2 */
__weak void vApplicationIdleHook( void )
{
}
/* USER CODE END 2 */

/* USER CODE BEGIN 4 */
__weak void vApplicationStackOverflowHook(xTaskHandle xTask, signed char *pcTaskName)
{
}
/* USER CODE END 4 */

/* USER CODE BEGIN 5 */
__weak void vApplicationMallocFailedHook(void)
{
}
/* USER CODE END 5 */

/* USER CODE BEGIN GET_IDLE_TASK_MEMORY */
static StaticTask_t xIdleTaskTCBBuffer;
static StackType_t xIdleStack[configMINIMAL_STACK_SIZE];

void vApplicationGetIdleTaskMemory( StaticTask_t **ppxIdleTaskTCBBuffer, StackType_t **ppxIdleTaskStackBuffer, uint32_t *pulIdleTaskStackSize )
{
  *ppxIdleTaskTCBBuffer = &xIdleTaskTCBBuffer;
  *ppxIdleTaskStackBuffer = &xIdleStack[0];
  *pulIdleTaskStackSize = configMINIMAL_STACK_SIZE;
}
/* USER CODE END GET_IDLE_TASK_MEMORY */

void MX_FREERTOS_Init(void) {

  /* Create the thread(s) */
  /* definition and creation of defaultTask */
  /*
   * Audio refill must preempt TouchGFX rendering. Both tasks at the same
   * priority allowed screen transitions to consume the DMA refill deadline.
   */
  /*
   * Measured high-water usage is below 200 words. Keep more than 5x margin
   * for audio processing and diagnostics.
   */
  osThreadDef(defaultTask, StartDefaultTask, osPriorityAboveNormal, 0, 1024);
  defaultTaskHandle = osThreadCreate(osThread(defaultTask), NULL);

  /* definition and creation of TouchGFXTask */
  /*
   * TouchGFX used about 570 words during screen-transition stress testing.
   * 2048 words preserves a wide margin for future UI changes.
   */
  osThreadDef(TouchGFXTask, TouchGFX_Task, osPriorityNormal, 0, 2048);
  TouchGFXTaskHandle = osThreadCreate(osThread(TouchGFXTask), NULL);

}

void StartDefaultTask(void const * argument)
{
  /* init code for USB_HOST */
  /* USER CODE BEGIN StartDefaultTask */

  setvbuf(stdout, NULL, _IONBF, 0);
    printf("Task started, mounting SD card...\r\n");

    printf("BSP_SD_IsDetected = %d (SD_PRESENT=1)\r\n", BSP_SD_IsDetected());

    uint8_t sd_init_ret = BSP_SD_Init();
    printf("BSP_SD_Init returned = %d (MSD_OK=0)\r\n", sd_init_ret);
    printf("HAL_SD_GetError = 0x%08lX\r\n", (unsigned long)HAL_SD_GetError(&hsd1));

    FRESULT mount_res = f_mount(&SDFatFs, "", 1);
    printf("f_mount result code = %d\r\n", mount_res);
    if(mount_res != FR_OK)
    {
      printf("f_mount FAILED!\r\n");
      Error_Handler();
    }
  printf("SD card mounted OK\r\n");

  AudioPlayer_ScanPlaylist();

  /* Infinite loop */
  for(;;)
  {
      uint8_t fillFirstHalf;
      uint8_t fillSecondHalf;
      int8_t trackDelta;
      int8_t volumeSteps;

      /*
       * Service DMA first. TouchGFX commands are intentionally handled only
       * after every pending audio half-buffer has been refilled.
       */
      taskENTER_CRITICAL();
      fillFirstHalf = HalfBufferNeedsFill;
      fillSecondHalf = FullBufferNeedsFill;
      HalfBufferNeedsFill = 0U;
      FullBufferNeedsFill = 0U;
      taskEXIT_CRITICAL();

      if (fillFirstHalf != 0U)
      {
          AudioPlayer_ServiceBuffer(&AudioBuffer[0]);
      }

      if (fillSecondHalf != 0U)
      {
          AudioPlayer_ServiceBuffer(
              &AudioBuffer[AUDIO_PLAYER_HALF_BUFFER_SIZE]
          );
      }

      taskENTER_CRITICAL();
      trackDelta = AudioTrackChangePending;
      AudioTrackChangePending = 0;
      volumeSteps = AudioVolumeChangePending;
      AudioVolumeChangePending = 0;
      taskEXIT_CRITICAL();

      /* Manual track changes have priority over automatic next. */
      if (trackDelta != 0)
      {
          AudioTrackFinished = 0U;
          AudioPlayer_ChangeTrack(trackDelta, "TRACK CHANGE");
      }
      else if (AudioTrackFinished != 0U)
      {
          AudioTrackFinished = 0U;
          AudioPlayer_ChangeTrack(1, "AUTO NEXT");
      }

      if (AudioPlayPauseRequested != 0U)
      {
          AudioPlayPauseRequested = 0U;

          if (PlayerState == PLAYER_STOPPED)
          {
              AudioPlayer_ResetDeadlineMisses();
              AudioPlayer_StartSelectedTrack("PLAY");
          }
          else if (PlayerState == PLAYER_PLAYING)
          {
              BSP_AUDIO_OUT_Pause();
              AudioPlayer_ClearTransferFlags();
              PlayerState = PLAYER_PAUSED;

              /* UART reporting is safe only after audio DMA is paused. */
              AudioBenchmark_Report();
              printf("Player state = PAUSED\r\n");
          }
          else if (PlayerState == PLAYER_PAUSED)
          {
              /* Finish UART output before DMA playback resumes. */
              printf("Player state = PLAYING\r\n");

              AudioPlayer_ClearTransferFlags();
              AudioPlayer_ResetDeadlineMisses();
              AudioBenchmark_Reset();
              BSP_AUDIO_OUT_Resume();
              PlayerState = PLAYER_PLAYING;
          }
      }

      if (volumeSteps != 0)
      {
          int newVolume =
              (int)AudioVolume + ((int)volumeSteps * 5);

          if (newVolume < 0)
          {
              newVolume = 0;
          }
          else if (newVolume > 100)
          {
              newVolume = 100;
          }

          AudioVolume = (uint8_t)newVolume;

          if (PlayerState != PLAYER_STOPPED)
          {
              BSP_AUDIO_OUT_SetVolume(AudioVolume);
          }

          /* Do not use blocking UART while the DMA stream is active. */
      }

      osDelay(1);
  }
  /* USER CODE END StartDefaultTask */
}

/* USER CODE BEGIN Application */

static void AudioPlayer_ClearTransferFlags(void)
{
    taskENTER_CRITICAL();
    HalfBufferNeedsFill = 0U;
    FullBufferNeedsFill = 0U;
    AudioTrackFinished = 0U;
    taskEXIT_CRITICAL();
}

static uint8_t AudioPlayer_IsWavFile(const char *filename)
{
    size_t length = strlen(filename);

    if (length < 4U)
    {
        return 0U;
    }

    const char *extension = &filename[length - 4U];

    return (extension[0] == '.') &&
           ((extension[1] == 'w') || (extension[1] == 'W')) &&
           ((extension[2] == 'a') || (extension[2] == 'A')) &&
           ((extension[3] == 'v') || (extension[3] == 'V'));
}

static void AudioPlayer_SortPlaylist(void)
{
    char temporary[PLAYLIST_FILENAME_SIZE];

    for (uint16_t i = 1U; i < trackCount; i++)
    {
        uint16_t position = i;
        memcpy(temporary, playlist[i], sizeof(temporary));

        while ((position > 0U) &&
               (strcmp(playlist[position - 1U], temporary) > 0))
        {
            memcpy(
                playlist[position],
                playlist[position - 1U],
                sizeof(playlist[position])
            );
            position--;
        }

        memcpy(playlist[position], temporary, sizeof(playlist[position]));
    }
}

static uint8_t AudioPlayer_ScanPlaylist(void)
{
    DIR directory;
    FILINFO fileInfo;
    FRESULT result;

    trackCount = 0U;
    currentTrack = 0;

    result = f_opendir(&directory, "/");

    if (result != FR_OK)
    {
        printf("Playlist scan failed: %d\r\n", result);
        return 0U;
    }

    while (trackCount < PLAYLIST_MAX_TRACKS)
    {
        result = f_readdir(&directory, &fileInfo);

        if ((result != FR_OK) || (fileInfo.fname[0] == '\0'))
        {
            break;
        }

        if (((fileInfo.fattrib & AM_DIR) != 0U) ||
            (AudioPlayer_IsWavFile(fileInfo.fname) == 0U))
        {
            continue;
        }

        size_t filenameLength = strlen(fileInfo.fname);

        if (filenameLength >= PLAYLIST_FILENAME_SIZE)
        {
            printf("Skipping long filename: %s\r\n", fileInfo.fname);
            continue;
        }

        memcpy(
            playlist[trackCount],
            fileInfo.fname,
            filenameLength + 1U
        );
        trackCount++;
    }

    f_closedir(&directory);

    if (result != FR_OK)
    {
        printf("Playlist scan failed: %d\r\n", result);
        trackCount = 0U;
        return 0U;
    }

    AudioPlayer_SortPlaylist();
    printf("Playlist: %u WAV file(s) found\r\n", (unsigned int)trackCount);

    for (uint16_t i = 0U; i < trackCount; i++)
    {
        printf("  %u: %s\r\n", (unsigned int)(i + 1U), playlist[i]);
    }

    return (trackCount > 0U) ? 1U : 0U;
}

static void AudioPlayer_ServiceBuffer(uint8_t *buffer)
{
    WavPlayer_FillHalf(buffer);

    if (AudioPlaying == 0U)
    {
        return;
    }

    AudioPipeline_Process(buffer);

    /*
     * Spectrum data is displayed much slower than the audio block rate.
     * Analyze every second block to leave more CPU time for TouchGFX.
     */
    spectrumDecimationCounter++;

    if (spectrumDecimationCounter >= 2U)
    {
        spectrumDecimationCounter = 0U;
        AudioFFT_Process(buffer);
    }
}

static uint8_t AudioPlayer_StartSelectedTrack(const char *reason)
{
    if (trackCount == 0U)
    {
        printf("No WAV files found on SD card\r\n");
        PlayerState = PLAYER_STOPPED;
        return 0U;
    }

    AudioPlayer_ClearTransferFlags();
    spectrumDecimationCounter = 0U;

    printf("%s -> %s\r\n", reason, playlist[currentTrack]);

    if (WavPlayer_Start(playlist[currentTrack]))
    {
        PlayerState = PLAYER_PLAYING;
        return 1;
    }

    PlayerState = PLAYER_STOPPED;
    printf("Playback start failed: %s\r\n", playlist[currentTrack]);
    return 0;
}

uint8_t AudioPlayer_GetCurrentTrackName(
    char *destination,
    uint16_t capacity
)
{
    if ((destination == NULL) || (capacity == 0U))
    {
        return 0U;
    }

    if (trackCount == 0U)
    {
        destination[0] = '\0';
        return 0U;
    }

    int selectedTrack = currentTrack;

    if ((selectedTrack < 0) || (selectedTrack >= (int)trackCount))
    {
        destination[0] = '\0';
        return 0U;
    }

    const char *filename = playlist[selectedTrack];
    size_t titleLength = strlen(filename);

    /* The player screen shows a title, not the WAV storage filename. */
    if ((titleLength >= 4U) &&
        (filename[titleLength - 4U] == '.'))
    {
        titleLength -= 4U;
    }

    if (titleLength >= (size_t)capacity)
    {
        titleLength = (size_t)capacity - 1U;
    }

    for (size_t i = 0U; i < titleLength; i++)
    {
        char character = filename[i];
        destination[i] =
            ((character == '_') || (character == '-')) ? ' ' : character;
    }

    destination[titleLength] = '\0';
    return 1U;
}

static uint8_t AudioPlayer_ChangeTrack(int8_t delta, const char *reason)
{
    if (trackCount == 0U)
    {
        printf("Track change ignored: playlist is empty\r\n");
        return 0U;
    }

    PlayerState = PLAYER_STOPPED;

    /*
     * Always stop DMA. At EOF AudioPlaying is already zero, but the previous
     * DMA stream can still be active until explicitly stopped.
     */
    WavPlayer_Stop();

    /* Let DMA and codec stop before starting the next track. */
    osDelay(15);
    AudioPlayer_ClearTransferFlags();

    int nextTrack = currentTrack + (int)delta;
    int availableTracks = (int)trackCount;

    nextTrack %= availableTracks;

    if (nextTrack < 0)
    {
        nextTrack += trackCount;
    }

    currentTrack = nextTrack;

    if (AudioPlayer_StartSelectedTrack(reason))
    {
        return 1;
    }

    /* Retry once after a transient SD or codec failure. */
    osDelay(30);
    AudioPlayer_ClearTransferFlags();

    return AudioPlayer_StartSelectedTrack("RETRY");
}

void AudioPlayer_RequestPlayPause(void)
{
    AudioPlayPauseRequested = 1;
}

void AudioPlayer_RequestNext(void)
{
    taskENTER_CRITICAL();

    if (AudioTrackChangePending < (int8_t)PLAYLIST_MAX_TRACKS)
    {
        AudioTrackChangePending++;
    }

    taskEXIT_CRITICAL();
}

void AudioPlayer_RequestPrevious(void)
{
    taskENTER_CRITICAL();

    if (AudioTrackChangePending > -(int8_t)PLAYLIST_MAX_TRACKS)
    {
        AudioTrackChangePending--;
    }

    taskEXIT_CRITICAL();
}

void AudioPlayer_RequestVolumeUp(void)
{
    taskENTER_CRITICAL();

    /* Coalesce repeated GUI events; one processed press equals one 5% step. */
    AudioVolumeChangePending = 1;

    taskEXIT_CRITICAL();
}

void AudioPlayer_RequestVolumeDown(void)
{
    taskENTER_CRITICAL();

    /* Coalesce repeated GUI events; one processed press equals one 5% step. */
    AudioVolumeChangePending = -1;

    taskEXIT_CRITICAL();
}

/* USER CODE END Application */
